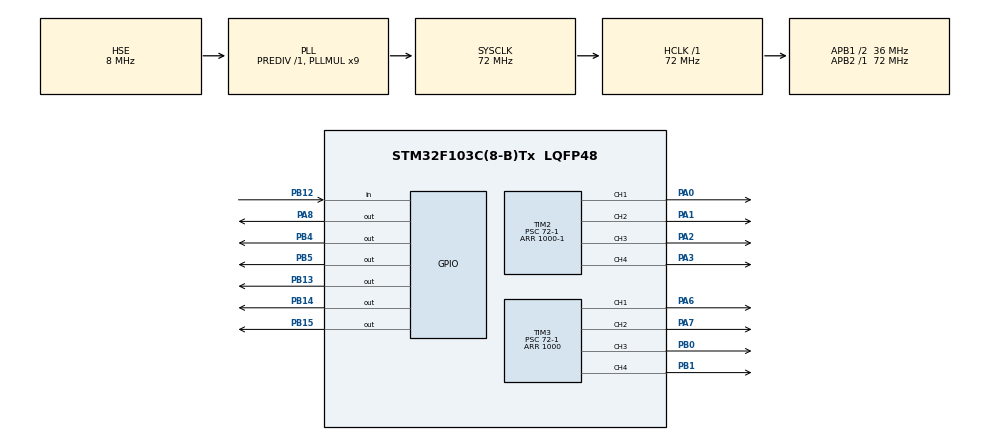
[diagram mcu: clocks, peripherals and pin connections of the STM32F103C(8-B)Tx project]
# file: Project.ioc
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FREERTOS.Queues01=RemoteQueue,16,Remote*,0,Dynamic,NULL,NULL
FREERTOS.Tasks01=Move,32,128,Move_task,As weak,NULL,Dynamic,NULL,NULL;AskData,24,128,AskData_task,As weak,NULL,Dynamic,NULL,NULL
FREERTOS.configUSE_PREEMPTION=1
Mcu.Family=STM32F1
Mcu.Name=STM32F103C(8-B)Tx
Mcu.Package=LQFP48
NVIC.PriorityGroup=NVIC_PRIORITYGROUP_4
NVIC.TIM4_IRQn=true\:15\:0\:false\:false\:true\:false\:false\:true\:true
NVIC.TimeBase=TIM4_IRQn
NVIC.TimeBaseIP=TIM4
PA0-WKUP.Signal=S_TIM2_CH1_ETR
PA1.Signal=S_TIM2_CH2
PA13.Mode=Serial_Wire
PA13.Signal=SYS_JTMS-SWDIO
PA14.Mode=Serial_Wire
PA14.Signal=SYS_JTCK-SWCLK
PA2.Signal=S_TIM2_CH3
PA3.Signal=S_TIM2_CH4
PA6.Signal=S_TIM3_CH1
PA7.Signal=S_TIM3_CH2
PA8.Signal=GPIO_Output
PB0.Signal=S_TIM3_CH3
PB1.Signal=S_TIM3_CH4
PB12.GPIO_PuPd=GPIO_PULLUP
PB12.Signal=GPIO_Input
PB13.Signal=GPIO_Output
PB14.Signal=GPIO_Output
PB15.PinState=GPIO_PIN_SET
PB15.Signal=GPIO_Output
PB4.GPIO_ModeDefaultOutputPP=GPIO_MODE_OUTPUT_OD
PB4.GPIO_PuPd=GPIO_NOPULL
PB4.Signal=GPIO_Output
PB5.GPIO_ModeDefaultOutputPP=GPIO_MODE_OUTPUT_OD
PB5.GPIO_PuPd=GPIO_NOPULL
PB5.Signal=GPIO_Output
PD0-OSC_IN.Mode=HSE-External-Oscillator
PD0-OSC_IN.Signal=RCC_OSC_IN
PD1-OSC_OUT.Mode=HSE-External-Oscillator
PD1-OSC_OUT.Signal=RCC_OSC_OUT
ProjectManager.HeapSize=0x200
ProjectManager.StackSize=0x400
ProjectManager.TargetToolchain=CMake
RCC.AHBFreq_Value=72000000
RCC.APB1CLKDivider=RCC_HCLK_DIV2
RCC.APB1Freq_Value=36000000
RCC.APB1TimFreq_Value=72000000
RCC.APB2Freq_Value=72000000
RCC.APB2TimFreq_Value=72000000
RCC.HCLKFreq_Value=72000000
RCC.PLLMUL=RCC_PLL_MUL9
RCC.PLLSourceVirtual=RCC_PLLSOURCE_HSE
RCC.SYSCLKFreq_VALUE=72000000
RCC.SYSCLKSource=RCC_SYSCLKSOURCE_PLLCLK
RCC.USBFreq_Value=72000000
SH.S_TIM2_CH1_ETR.0=TIM2_CH1,PWM Generation1 CH1
SH.S_TIM2_CH2.0=TIM2_CH2,PWM Generation2 CH2
SH.S_TIM2_CH3.0=TIM2_CH3,PWM Generation3 CH3
SH.S_TIM2_CH4.0=TIM2_CH4,PWM Generation4 CH4
SH.S_TIM3_CH1.0=TIM3_CH1,PWM Generation1 CH1
SH.S_TIM3_CH2.0=TIM3_CH2,PWM Generation2 CH2
SH.S_TIM3_CH3.0=TIM3_CH3,PWM Generation3 CH3
SH.S_TIM3_CH4.0=TIM3_CH4,PWM Generation4 CH4
TIM2.Channel-PWM\ Generation1\ CH1=TIM_CHANNEL_1
TIM2.Channel-PWM\ Generation2\ CH2=TIM_CHANNEL_2
TIM2.Channel-PWM\ Generation3\ CH3=TIM_CHANNEL_3
TIM2.Channel-PWM\ Generation4\ CH4=TIM_CHANNEL_4
TIM2.Period=1000-1
TIM2.Prescaler=72-1
TIM3.Channel-PWM\ Generation1\ CH1=TIM_CHANNEL_1
TIM3.Channel-PWM\ Generation2\ CH2=TIM_CHANNEL_2
TIM3.Channel-PWM\ Generation3\ CH3=TIM_CHANNEL_3
TIM3.Channel-PWM\ Generation4\ CH4=TIM_CHANNEL_4
TIM3.Period=1000
TIM3.Prescaler=72-1
VP_FREERTOS_VS_CMSIS_V2.Mode=CMSIS_V2
VP_SYS_VS_tim4.Mode=TIM4
VP_TIM2_VS_ClockSourceINT.Mode=Internal
board=custom

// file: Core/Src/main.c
/* USER CODE BEGIN Header */
/**
  ******************************************************************************
  * @file           : main.c
  * @brief          : Main program body
  ******************************************************************************
  * @attention
  *
  * Copyright (c) 2025 STMicroelectronics.
  * All rights reserved.
  *
  * This software is licensed under terms that can be found in the LICENSE file
  * in the root directory of this software component.
  * If no LICENSE file comes with this software, it is provided AS-IS.
  *
  ******************************************************************************
  */
/* USER CODE END Header */
#include "main.h"
#include "cmsis_os.h"
#include "tim.h"
#include "gpio.h"

/* USER CODE BEGIN Includes */
#include "OLED.h"
#include "nrf24l01.h"
/* USER CODE END Includes */

void SystemClock_Config(void);
void MX_FREERTOS_Init(void);

int main(void)
{

  /* MCU Configuration--------------------------------------------------------*/

  /* Reset of all peripherals, Initializes the Flash interface and the Systick. */
  HAL_Init();

  /* Configure the system clock */
  SystemClock_Config();

  /* Initialize all configured peripherals */
  MX_GPIO_Init();
  MX_TIM2_Init();
  MX_TIM3_Init();
  /* USER CODE BEGIN 2 */

  OLED_Init();//初始化OLED屏幕
  NRF24L01_Init();//初始化nrf24l01模块

  HAL_TIM_PWM_Start(&htim2, TIM_CHANNEL_1);
  HAL_TIM_PWM_Start(&htim2, TIM_CHANNEL_2);
  HAL_TIM_PWM_Start(&htim2, TIM_CHANNEL_3);//使能pwm通道，控制电机
  HAL_TIM_PWM_Start(&htim2, TIM_CHANNEL_4);
  HAL_TIM_PWM_Start(&htim3, TIM_CHANNEL_1);
  HAL_TIM_PWM_Start(&htim3, TIM_CHANNEL_2);
  HAL_TIM_PWM_Start(&htim3, TIM_CHANNEL_3);
  HAL_TIM_PWM_Start(&htim3, TIM_CHANNEL_4);
  /* USER CODE END 2 */

  /* Init scheduler */
  osKernelInitialize();

  /* Call init function for freertos objects (in cmsis_os2.c) */
  MX_FREERTOS_Init();

  /* Start scheduler */
  osKernelStart();

  /* We should never get here as control is now taken by the scheduler */

  /* Infinite loop */
  while (1)
  {

  }
}

void SystemClock_Config(void)
{
  RCC_OscInitTypeDef RCC_OscInitStruct = {0};
  RCC_ClkInitTypeDef RCC_ClkInitStruct = {0};

  /** Initializes the RCC Oscillators according to the specified parameters
  * in the RCC_OscInitTypeDef structure.
  */
  RCC_OscInitStruct.OscillatorType = RCC_OSCILLATORTYPE_HSE;
  RCC_OscInitStruct.HSEState = RCC_HSE_ON;
  RCC_OscInitStruct.HSEPredivValue = RCC_HSE_PREDIV_DIV1;
  RCC_OscInitStruct.HSIState = RCC_HSI_ON;
  RCC_OscInitStruct.PLL.PLLState = RCC_PLL_ON;
  RCC_OscInitStruct.PLL.PLLSource = RCC_PLLSOURCE_HSE;
  RCC_OscInitStruct.PLL.PLLMUL = RCC_PLL_MUL9;
  if (HAL_RCC_OscConfig(&RCC_OscInitStruct) != HAL_OK)
  {
    Error_Handler();
  }

  /** Initializes the CPU, AHB and APB buses clocks
  */
  RCC_ClkInitStruct.ClockType = RCC_CLOCKTYPE_HCLK|RCC_CLOCKTYPE_SYSCLK
                              |RCC_CLOCKTYPE_PCLK1|RCC_CLOCKTYPE_PCLK2;
  RCC_ClkInitStruct.SYSCLKSource = RCC_SYSCLKSOURCE_PLLCLK;
  RCC_ClkInitStruct.AHBCLKDivider = RCC_SYSCLK_DIV1;
  RCC_ClkInitStruct.APB1CLKDivider = RCC_HCLK_DIV2;
  RCC_ClkInitStruct.APB2CLKDivider = RCC_HCLK_DIV1;

  if (HAL_RCC_ClockConfig(&RCC_ClkInitStruct, FLASH_LATENCY_2) != HAL_OK)
  {
    Error_Handler();
  }
}

void HAL_TIM_PeriodElapsedCallback(TIM_HandleTypeDef *htim)
{
  if (htim->Instance == TIM4) {
    HAL_IncTick();
  }
}

void Error_Handler(void)
{
  __disable_irq();
  while (1)
  {
  }
}

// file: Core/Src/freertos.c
/* USER CODE BEGIN Header */
/**
  ******************************************************************************
  * File Name          : freertos.c
  * Description        : Code for freertos applications
  ******************************************************************************
  * @attention
  *
  * Copyright (c) 2026 STMicroelectronics.
  * All rights reserved.
  *
  * This software is licensed under terms that can be found in the LICENSE file
  * in the root directory of this software component.
  * If no LICENSE file comes with this software, it is provided AS-IS.
  *
  ******************************************************************************
  */
/* USER CODE END Header */

#include "FreeRTOS.h"
#include "task.h"
#include "main.h"
#include "cmsis_os.h"

/* Definitions for Move */
osThreadId_t MoveHandle;
const osThreadAttr_t Move_attributes = {
  .name = "Move",
  .stack_size = 128 * 4,
  .priority = (osPriority_t) osPriorityAboveNormal,
};
/* Definitions for AskData */
osThreadId_t AskDataHandle;
const osThreadAttr_t AskData_attributes = {
  .name = "AskData",
  .stack_size = 128 * 4,
  .priority = (osPriority_t) osPriorityNormal,
};
/* Definitions for RemoteQueue */
osMessageQueueId_t RemoteQueueHandle;
const osMessageQueueAttr_t RemoteQueue_attributes = {
  .name = "RemoteQueue"
};

void Move_task(void *argument);
void AskData_task(void *argument);

void MX_FREERTOS_Init(void); /* (MISRA C 2004 rule 8.1) */

void MX_FREERTOS_Init(void) {

  /* Create the queue(s) */
  /* creation of RemoteQueue */
  RemoteQueueHandle = osMessageQueueNew (16, sizeof(Remote*), &RemoteQueue_attributes);

  /* Create the thread(s) */
  /* creation of Move */
  MoveHandle = osThreadNew(Move_task, NULL, &Move_attributes);

  /* creation of AskData */
  AskDataHandle = osThreadNew(AskData_task, NULL, &AskData_attributes);

}

__weak void Move_task(void *argument)
{
  for(;;)
  {
    osDelay(1);
  }
}

__weak void AskData_task(void *argument)
{
  for(;;)
  {
    osDelay(1);
  }
}
